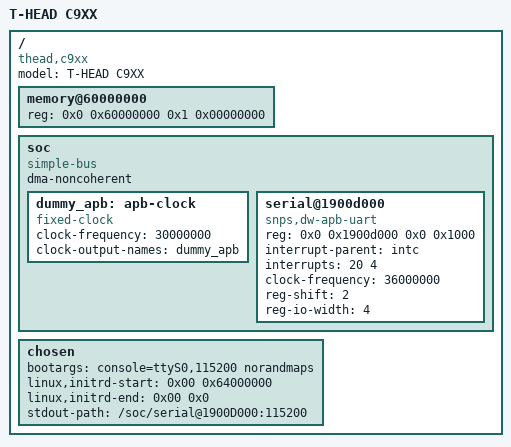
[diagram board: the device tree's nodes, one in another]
/dts-v1/;

/ {
	model = "T-HEAD C9XX";
	compatible = "thead,c9xx";
	#address-cells = <2>;
	#size-cells = <2>;

	memory@60000000 {
		device_type = "memory";
		reg = <0x0 0x60000000 0x1 0x00000000>;
	};

	/include/ "ntrace-memory.dtsi"
	/include/ "cpu.dtsi"
	/include/ "pmu.dtsi"

	soc: soc {
		#address-cells = <2>;
		#size-cells = <2>;
		compatible = "simple-bus";
		dma-noncoherent;
		ranges;

		/include/ "intc.dtsi"

		dummy_apb: apb-clock {
			#clock-cells = <0>;
			compatible = "fixed-clock";
			clock-frequency = <30000000>;
			clock-output-names = "dummy_apb";
		};

		serial@1900d000 {
			compatible = "snps,dw-apb-uart";
			reg = <0x0 0x1900d000 0x0 0x1000>;
			interrupt-parent = <&intc>;
			interrupts = <20 4>;
			clock-frequency = <36000000>;
			clock-names = "baudclk";
			reg-shift = <2>;
			reg-io-width = <4>;
		};

		/include/ "gmac.dtsi"
		/include/ "ntrace-1core.dtsi"
		/include/ "ntrace-2core.dtsi"
	};

	chosen {
		bootargs = "console=ttyS0,115200 norandmaps";
		linux,initrd-start = <0x00 0x64000000>;
		linux,initrd-end = <0x00 0x0>;
		stdout-path = "/soc/serial@1900D000:115200";
	};
};

/* If more than 8 cores, uncomment the follow line */
// /include/ "32cores.dtsi"

